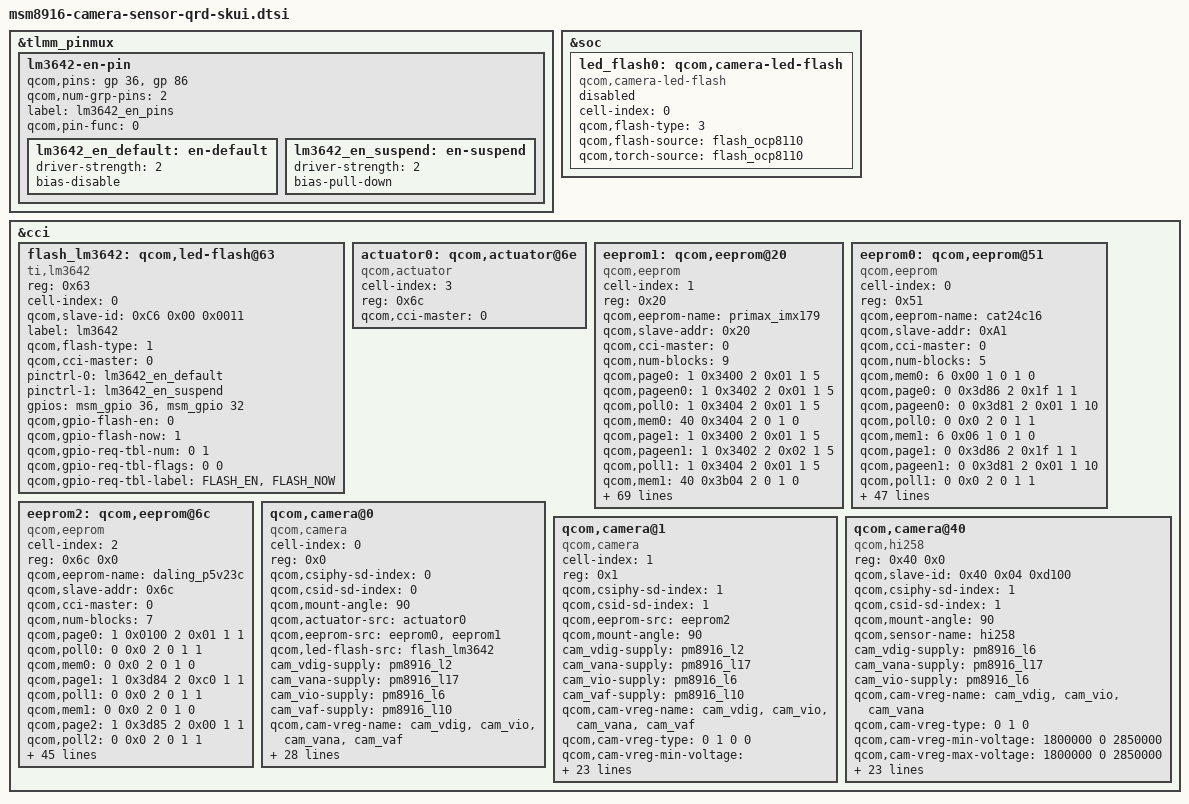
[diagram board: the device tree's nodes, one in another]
/*
 * Copyright (c) 2014, The Linux Foundation. All rights reserved.
 *
 * This program is free software; you can redistribute it and/or modify
 * it under the terms of the GNU General Public License version 2 and
 * only version 2 as published by the Free Software Foundation.
 *
 * This program is distributed in the hope that it will be useful,
 * but WITHOUT ANY WARRANTY; without even the implied warranty of
 * MERCHANTABILITY or FITNESS FOR A PARTICULAR PURPOSE.  See the
 * GNU General Public License for more details.
 */
&tlmm_pinmux {
       lm3642-en-pin {
            //qcom,pins = <&gp 31>, <&gp 86>;
            qcom,pins = <&gp 36>, <&gp 86>;  //add by YangRujin for gp_clk control bl.
            qcom,num-grp-pins = <2>;
            label = "lm3642_en_pins";
            qcom,pin-func = <0>;

            lm3642_en_default: en-default {
                       driver-strength = <2>;
                       bias-disable;
            };  
            
            lm3642_en_suspend: en-suspend {
                driver-strength = <2>;
                bias-pull-down;
            };  
    }; 
};

&soc {
	led_flash0: qcom,camera-led-flash {
		cell-index = <0>;
                status = "disabled";
		compatible = "qcom,camera-led-flash";
		qcom,flash-type = <3>;
		qcom,flash-source = <&flash_ocp8110>;
		qcom,torch-source = <&flash_ocp8110>;
	};
};


&cci {
        flash_lm3642:qcom,led-flash@63 {
                 reg = <0x63>;
                 cell-index = <0>;
                 qcom,slave-id = <0xC6 0x00 0x0011>;
                 compatible = "ti,lm3642";
                 label = "lm3642";
                 qcom,flash-type = <1>;
		 qcom,cci-master = <0>;
                 pinctrl-names = "cam_flash_default","cam_flash_suspend";
                 pinctrl-0 = <&lm3642_en_default>;
                 pinctrl-1 = <&lm3642_en_suspend>;
                 gpios = <&msm_gpio 36 0>,
                         <&msm_gpio 32 0>;
                 //gpios = <&msm_gpio 29 0>,  //sda 
                 //        <&msm_gpio 30 0>;  //scl
                 qcom,gpio-flash-en = <0>;
                 qcom,gpio-flash-now = <1>;
                 qcom,gpio-req-tbl-num = <0 1>; 
                 qcom,gpio-req-tbl-flags = <0 0>; 
                 qcom,gpio-req-tbl-label = "FLASH_EN",
                                           "FLASH_NOW";
             };  

	actuator0: qcom,actuator@6e {
		cell-index = <3>;
		reg = <0x6c>;
		compatible = "qcom,actuator";
		qcom,cci-master = <0>;
	};


    eeprom1: qcom,eeprom@20 {
		cell-index = <1>;
		reg = <0x20>;
		qcom,eeprom-name = "primax_imx179";
		compatible = "qcom,eeprom";
		qcom,slave-addr = <0x20>;
		qcom,cci-master = <0>;
		qcom,num-blocks = <9>;

		qcom,page0 = <1 0x3400 2 0x01 1 5>;
		qcom,pageen0 = <1 0x3402 2 0x01 1 5>;
        qcom,poll0 = <1 0x3404 2 0x01 1 5>;
		qcom,mem0 = <40 0x3404 2 0 1 0>;

		qcom,page1 = <1 0x3400 2 0x01 1 5>;
		qcom,pageen1 = <1 0x3402 2 0x02 1 5>;
		qcom,poll1 = <1 0x3404 2 0x01 1 5>;
		qcom,mem1 = <40 0x3b04 2 0 1 0>;

		qcom,page2 = <1 0x3400 2 0x01 1 5>;
		qcom,pageen2 = <1 0x3402 2 0x03 1 5>;
		qcom,poll2 = <1 0x3404 2 0x01 1 5>;
		qcom,mem2 = <40 0x3404 2 0 1 0>;

        qcom,page3 = <1 0x3400 2 0x01 1 5>;
		qcom,pageen3 = <1 0x3402 2 0x04 1 5>;
		qcom,poll3 = <1 0x3404 2 0x01 1 5>;
		qcom,mem3 = <40 0x3404 2 0 1 0>;

        qcom,page4 = <1 0x3400 2 0x01 1 5>;
		qcom,pageen4 = <1 0x3400 2 0x05 1 5>;
		qcom,poll4 = <1 0x3404 2 0x01 1 5>;
		qcom,mem4 = <40 0x3404 2 0 1 0>;

		qcom,page5 = <1 0x3400 2 0x01 1 5>;
		qcom,pageen5 = <1 0x3402 2 0x06 1 5>;
        qcom,poll5 = <1 0x3404 2 0x01 1 5>;
		qcom,mem5 = <40 0x3404 2 0 1 0>;

        qcom,page6 = <1 0x3400 2 0x01 1 5>;
		qcom,pageen6 = <1 0x3402 2 0x07 1 5>;
        qcom,poll6 = <1 0x3404 2 0x01 1 5>;
		qcom,mem6 = <40 0x3404 2 0 1 0>;

        qcom,page7 = <1 0x3400 2 0x01 1 5>;
		qcom,pageen7 = <1 0x3402 2 0x08 1 5>;
        qcom,poll7 = <1 0x3404 2 0x01 1 5>;
		qcom,mem7 = <40 0x3404 2 0 1 0>;

        qcom,page8 = <1 0x3400 2 0x01 1 5>;
		qcom,pageen8 = <1 0x3402 2 0x09 1 5>;
        qcom,poll8 = <1 0x3404 2 0x01 1 5>;
		qcom,mem8 = <40 0x3404 2 0 1 0>;

		cam_vdig-supply = <&pm8916_l2>;
		cam_vana-supply = <&pm8916_l17>;
		cam_vio-supply = <&pm8916_l6>;
		cam_vaf-supply = <&pm8916_l10>;

		qcom,cam-vreg-name = "cam_vdig", "cam_vio", "cam_vana",
							"cam_vaf";
		qcom,cam-vreg-type = <0 1 0 0>;
		qcom,cam-vreg-min-voltage = <1200000 0 2850000 2800000>;
		qcom,cam-vreg-max-voltage = <1200000 0 2850000 2800000>;
		qcom,cam-vreg-op-mode = <200000 0 80000 100000>;
		pinctrl-names = "cam_default", "cam_suspend";
		pinctrl-0 = <&cam_sensor_mclk0_default &cam_sensor_rear_default>;
		pinctrl-1 = <&cam_sensor_mclk0_sleep &cam_sensor_rear_sleep>;
		qcom,gpio-no-mux = <0>;
		gpios = <&msm_gpio 26 0>,
			<&msm_gpio 35 0>,
			<&msm_gpio 34 0>,
            <&msm_gpio 121 0>;//gpio_m
			//<&msm_gpio 17 0>;
		qcom,gpio-reset = <1>;
		qcom,gpio-standby = <2>;
        qcom,gpio-af-pwdm = <3>;
        //qcom,gpio-vdig = <4>;
		qcom,gpio-req-tbl-num = <0 1 2 3>;
		qcom,gpio-req-tbl-flags = <1 0 0 0>;
		qcom,gpio-req-tbl-label = "CAMIF_MCLK",
			"CAM_RESET1",
			"CAM_STANDBY",
            "CAM_AF_PWDM";
		qcom,gpio-set-tbl-num = <1 1>;
		qcom,gpio-set-tbl-flags = <0 2>;
		qcom,gpio-set-tbl-delay = <1000 4000>;
		qcom,csi-lane-assign = <0x4320>;
		qcom,csi-lane-mask = <0x3>;
		qcom,cam-power-seq-type = "sensor_vreg", "sensor_vreg", "sensor_vreg",
			"sensor_gpio", "sensor_gpio" , "sensor_clk";
		qcom,cam-power-seq-val = "cam_vdig", "cam_vana", "cam_vio",
			"sensor_gpio_reset", "sensor_gpio_standby","sensor_cam_mclk";

        qcom,cam-power-seq-cfg-val = <1 1 1 1 1 23880000>;
		qcom,cam-power-seq-delay = <1 1 1 30 30 5>;

		clocks = <&clock_gcc clk_mclk0_clk_src>,
			<&clock_gcc clk_gcc_camss_mclk0_clk>;
		clock-names = "cam_src_clk", "cam_clk";
	};


	eeprom0: qcom,eeprom@51{
		cell-index = <0>;
		reg = <0x51>;
		qcom,eeprom-name = "cat24c16";
		compatible = "qcom,eeprom";
		qcom,slave-addr = <0xA1>;
		qcom,cci-master = <0>;
		qcom,num-blocks = <5>;

		qcom,mem0 = <6 0x00 1 0 1 0>;
		qcom,page0 = <0 0x3d86 2 0x1f 1 1>;
		qcom,pageen0 = <0 0x3d81 2 0x01 1 10>;
		qcom,poll0 = <0 0x0 2 0 1 1>;

		qcom,mem1 = <6 0x06 1 0 1 0>;
		qcom,page1 = <0 0x3d86 2 0x1f 1 1>;
		qcom,pageen1 = <0 0x3d81 2 0x01 1 10>;
		qcom,poll1 = <0 0x0 2 0 1 1>;

		qcom,mem2 = <6 0x0C 1 0 1 0>;
		qcom,page2 = <0 0x3d86 2 0x1f 1 1>;
		qcom,pageen2 = <0 0x3d81 2 0x01 1 10>;
		qcom,poll2 = <0 0x0 2 0 1 1>;

		qcom,mem3 = <256 0x00 1 0 1 0>;
		qcom,page3 = <0 0x3d86 2 0x1f 1 1>;
		qcom,pageen3 = <0 0x3d81 2 0x01 1 10>;
		qcom,poll3 = <0 0x0 2 0 1 1>;
                qcom,saddr3 = <0xA3>;

		qcom,mem4 = <248 0x00 1 0 1 0>;
		qcom,page4 = <0 0x3d86 2 0x1f 1 1>;
		qcom,pageen4 = <0 0x3d81 2 0x01 1 10>;
		qcom,poll4 = <0 0x0 2 0 1 1>;
                qcom,saddr4 = <0xA5>;

		cam_vana-supply = <&pm8916_l17>;
		cam_vio-supply = <&pm8916_l6>;
		cam_vaf-supply = <&pm8916_l10>;
		qcom,cam-vreg-name = "cam_vdig", "cam_vio", "cam_vana",
							"cam_vaf";
		qcom,cam-vreg-type = <0 1 0 0>;
		qcom,cam-vreg-min-voltage = <2100000 0 2850000 2800000>;
		qcom,cam-vreg-max-voltage = <2100000 0 2850000 2800000>;
		qcom,cam-vreg-op-mode = <200000 0 80000 100000>;
		pinctrl-names = "cam_default", "cam_suspend";
		pinctrl-0 = <&cam_sensor_mclk0_default &cam_sensor_rear_default>;
		pinctrl-1 = <&cam_sensor_mclk0_sleep &cam_sensor_rear_sleep>;
		gpios = <&msm_gpio 26 0>,
			<&msm_gpio 35 0>,
			<&msm_gpio 34 0>,
			<&msm_gpio 17 0>;
		qcom,gpio-reset = <1>;
		qcom,gpio-standby = <2>;
                qcom,gpio-vdig = <3>;
		qcom,gpio-req-tbl-num = <0 1 2 3>;
		qcom,gpio-req-tbl-flags = <1 0 0 0>;
		qcom,gpio-req-tbl-label = "CAMIF_MCLK",
			"CAM_RESET1",
			"CAM_STANDBY",
                        "CAM_VDIG";

		qcom,cam-power-seq-type = "sensor_vreg",
			"sensor_gpio", "sensor_gpio",
			"sensor_clk";
		qcom,cam-power-seq-val = "cam_vaf",
			"sensor_gpio_reset",
			"sensor_gpio_standby",
			"sensor_cam_mclk" ;
		qcom,cam-power-seq-cfg-val = <1 1 1 23880000>;
		qcom,cam-power-seq-delay = <1 10 10 5>;

		clocks = <&clock_gcc clk_mclk0_clk_src>,
			<&clock_gcc clk_gcc_camss_mclk0_clk>;
		clock-names = "cam_src_clk", "cam_clk";
	};

	// OV5648
        eeprom2: qcom,eeprom@6c{
                cell-index = <2>;
                reg = <0x6c 0x0>;
                qcom,eeprom-name = "daling_p5v23c";
                compatible = "qcom,eeprom";
                qcom,slave-addr = <0x6c>;
                qcom,cci-master = <0>;
                qcom,num-blocks = <7>;
    
                qcom,page0 = <1 0x0100 2 0x01 1 1>; 
                qcom,poll0 = <0 0x0 2 0 1 1>; 
                qcom,mem0 = <0 0x0 2 0 1 0>; 

                qcom,page1 = <1 0x3d84 2 0xc0 1 1>; 
                qcom,poll1 = <0 0x0 2 0 1 1>; 
                qcom,mem1 = <0 0x0 2 0 1 0>; 
            
                qcom,page2 = <1 0x3d85 2 0x00 1 1>; 
                qcom,poll2 = <0 0x0 2 0 1 1>; 
                qcom,mem2 = <0 0x0 2 0 1 0>; 
            
                qcom,page3 = <1 0x3d86 2 0x0f 1 1>; 
                qcom,pageen3 = <1 0x3d81 2 0x01 1 10>;
                qcom,poll3 = <0 0x0 2 0 1 1>; 
                qcom,mem3 = <16 0x3d00 2 0 1 0>;

                qcom,page4 = <1 0x3d84 2 0xc0 1 1>;
                qcom,poll4 = <0 0x0 2 0 1 1>;
                qcom,mem4 = <0 0x0 2 0 1 0>;
            
                qcom,page5 = <1 0x3d85 2 0x10 1 1>;
                qcom,poll5 = <0 0x0 2 0 1 1>;
                qcom,mem5 = <0 0x0 2 0 1 0>;
            
                qcom,page6 = <1 0x3d86 2 0x1f 1 1>;
                qcom,pageen6 = <1 0x3d81 2 0x01 1 10>;
                qcom,poll6 = <0 0x0 2 0 1 1>;
                qcom,mem6 = <16 0x3d00 2 0 1 0>;

		cam_vana-supply = <&pm8916_l17>;
		cam_vio-supply = <&pm8916_l6>;
		qcom,cam-vreg-name = "cam_vana", "cam_vio"; // Jiangde
		qcom,cam-vreg-type = <1 0>;
		qcom,cam-vreg-min-voltage = <0 2850000>;
		qcom,cam-vreg-max-voltage = <0 2850000>;
		qcom,cam-vreg-op-mode = <0 80000>;
		pinctrl-names = "cam_default", "cam_suspend";
		pinctrl-0 = <&cam_sensor_mclk1_default &cam_sensor_front_default>;
		pinctrl-1 = <&cam_sensor_mclk1_sleep &cam_sensor_front_sleep>;
		gpios = <&msm_gpio 27 0>,
			<&msm_gpio 28 0>,
			<&msm_gpio 33 0>,
			<&msm_gpio 119 0>; // Jiangde
		qcom,gpio-reset = <1>;
		qcom,gpio-standby = <2>;
		qcom,gpio-vana = <3>; // Jiangde
		qcom,gpio-req-tbl-num = <0 1 2 3>;   // Jiangde
		qcom,gpio-req-tbl-flags = <1 0 0 0>; // Jiangde
		qcom,gpio-req-tbl-label = "CAMIF_MCLK",
			"CAM_RESET",
			"CAM_STANDBY",
			"CAM_VANA"; // Jiangde
                
		qcom,cam-power-seq-type = "sensor_vreg", 
			"sensor_gpio", // Jiangde
			"sensor_gpio",
			"sensor_gpio",
			"sensor_clk";
		qcom,cam-power-seq-val = "cam_vio", 
			"sensor_gpio_vana", // Jiangde
			"sensor_gpio_standby",
			"sensor_gpio_reset",
			"sensor_cam_mclk" ;
		qcom,cam-power-seq-cfg-val = <1 1 1 1 23880000>;
		qcom,cam-power-seq-delay = <1 1 10 10 5>;

		clocks = <&clock_gcc clk_mclk1_clk_src>,<&clock_gcc clk_gcc_camss_mclk1_clk>;
		clock-names = "cam_src_clk", "cam_clk";
	};

	qcom,camera@0 {
		cell-index = <0>;
		compatible = "qcom,camera";
		reg = <0x0>;
		qcom,csiphy-sd-index = <0>;
		qcom,csid-sd-index = <0>;
		qcom,mount-angle = <90>;
		qcom,actuator-src = <&actuator0>;
		qcom,eeprom-src = <&eeprom0 &eeprom1>;
		qcom,led-flash-src = <&flash_lm3642>;
		cam_vdig-supply = <&pm8916_l2>;
		cam_vana-supply = <&pm8916_l17>;
		cam_vio-supply = <&pm8916_l6>;
		cam_vaf-supply = <&pm8916_l10>;
		qcom,cam-vreg-name = "cam_vdig", "cam_vio", "cam_vana",
							"cam_vaf";
		qcom,cam-vreg-type = <0 1 0 0>;
		qcom,cam-vreg-min-voltage = <1200000 0 2850000 2800000>;
		qcom,cam-vreg-max-voltage = <1200000 0 2850000 2800000>;
		qcom,cam-vreg-op-mode = <200000 0 80000 100000>;
		pinctrl-names = "cam_default", "cam_suspend";
		pinctrl-0 = <&cam_sensor_mclk0_default &cam_sensor_rear_default>;
		pinctrl-1 = <&cam_sensor_mclk0_sleep &cam_sensor_rear_sleep>;
		gpios = <&msm_gpio 26 0>,
			<&msm_gpio 35 0>,
			<&msm_gpio 34 0>,
			<&msm_gpio 121 0>,//gpio_m
			<&msm_gpio 17 0>,
			<&msm_gpio 119 0>;
		qcom,gpio-reset = <1>;
		qcom,gpio-standby = <2>;
		qcom,gpio-af-pwdm = <3>;
                qcom,gpio-vdig = <4>;
                qcom,gpio-vana = <5>;
		qcom,gpio-req-tbl-num = <0 1 2 3 4 5>;
		qcom,gpio-req-tbl-flags = <1 0 0 0 0 0>;
		qcom,gpio-req-tbl-label = "CAMIF_MCLK",
			"CAM_RESET1",
			"CAM_STANDBY",
			"CAM_AF_PWDM",
            "CAM_VDIG",
            "CAM_VANA";
		qcom,sensor-position = <0>;
		qcom,sensor-mode = <0>;
		qcom,cci-master = <0>;
		qcom,mclk-23880000;
		status = "ok";
		clocks = <&clock_gcc clk_mclk0_clk_src>,
				<&clock_gcc clk_gcc_camss_mclk0_clk>;
		clock-names = "cam_src_clk", "cam_clk";
	};

	qcom,camera@1 {
		cell-index = <1>;
		compatible = "qcom,camera";
		reg = <0x1>;
		qcom,csiphy-sd-index = <1>;
		qcom,csid-sd-index = <1>;
		qcom,eeprom-src = <&eeprom2>;
		qcom,mount-angle = <90>;
		cam_vdig-supply = <&pm8916_l2>;
		cam_vana-supply = <&pm8916_l17>;
		cam_vio-supply = <&pm8916_l6>;
		cam_vaf-supply = <&pm8916_l10>;
		qcom,cam-vreg-name = "cam_vdig", "cam_vio", "cam_vana",
							"cam_vaf";
		qcom,cam-vreg-type = <0 1 0 0>;
		qcom,cam-vreg-min-voltage = <1500000 0 2850000 2800000>;
		qcom,cam-vreg-max-voltage = <1500000 0 2850000 2800000>;
		qcom,cam-vreg-op-mode = <200000 0 80000 100000>;
		pinctrl-names = "cam_default", "cam_suspend";
		pinctrl-0 = <&cam_sensor_mclk1_default &cam_sensor_front_default>;
		pinctrl-1 = <&cam_sensor_mclk1_sleep &cam_sensor_front_sleep>;
		gpios = <&msm_gpio 27 0>,
			<&msm_gpio 28 0>,
			<&msm_gpio 33 0>,
			<&msm_gpio 119 0>;
		qcom,gpio-reset = <1>;
		qcom,gpio-standby = <2>;
		qcom,gpio-vdig = <3>;
		qcom,gpio-req-tbl-num = <0 1 2 3>;
		qcom,gpio-req-tbl-flags = <1 0 0 0>;
		qcom,gpio-req-tbl-label = "CAMIF_MCLK",
			"CAM_RESET",
			"CAM_STANDBY",
			"CAM_VDIG";
		qcom,sensor-position = <1>;
		qcom,sensor-mode = <0>;
		qcom,cci-master = <0>;
		qcom,mclk-23880000;
		status = "ok";
		clocks = <&clock_gcc clk_mclk1_clk_src>,
				<&clock_gcc clk_gcc_camss_mclk1_clk>;
		clock-names = "cam_src_clk", "cam_clk";
	};

   qcom,camera@40 {
           compatible = "qcom,hi258";
           reg = <0x40 0x0>;
           qcom,slave-id = <0x40 0x04 0xd100>;
           qcom,csiphy-sd-index = <1>;
           qcom,csid-sd-index = <1>;
           qcom,mount-angle = <90>;
           qcom,sensor-name = "hi258";
           cam_vdig-supply = <&pm8916_l6>;
           cam_vana-supply = <&pm8916_l17>;
           cam_vio-supply = <&pm8916_l6>;
           qcom,cam-vreg-name = "cam_vdig", "cam_vio", "cam_vana";
           qcom,cam-vreg-type = <0 1 0>;
           qcom,cam-vreg-min-voltage = <1800000 0 2850000>;
           qcom,cam-vreg-max-voltage = <1800000 0 2850000>;
           qcom,cam-vreg-op-mode = <200000 0 80000>;
           pinctrl-names = "cam_default", "cam_suspend";
           pinctrl-0 = <&cam_sensor_mclk1_default &cam_sensor_front_default>;
           pinctrl-1 = <&cam_sensor_mclk1_sleep &cam_sensor_front_sleep>;
           gpios = <&msm_gpio 27 0>,
                   <&msm_gpio 28 0>,
                   <&msm_gpio 33 0>;
           qcom,gpio-reset = <1>;
           qcom,gpio-standby = <2>;
           qcom,gpio-req-tbl-num = <0 1 2>;
           qcom,gpio-req-tbl-flags = <1 0 0>;
           qcom,gpio-req-tbl-label = "CAMIF_MCLK",
                                   "CAM_RESET",
                                   "CAM_STANDBY";
           qcom,gpio-set-tbl-num = <1 1>;
           qcom,gpio-set-tbl-flags = <0 2>;
           qcom,gpio-set-tbl-delay = <1000 4000>;
           qcom,csi-lane-assign = <0x4320>;
           qcom,csi-lane-mask = <0x3>;
           qcom,sensor-position = <1>;
           qcom,sensor-mode = <0>;
           qcom,cci-master = <0>;
           qcom,mclk-23880000;
           status = "ok";
           clocks = <&clock_gcc clk_mclk1_clk_src>,
                   <&clock_gcc clk_gcc_camss_mclk1_clk>;
           clock-names = "cam_src_clk", "cam_clk";
    };

};
